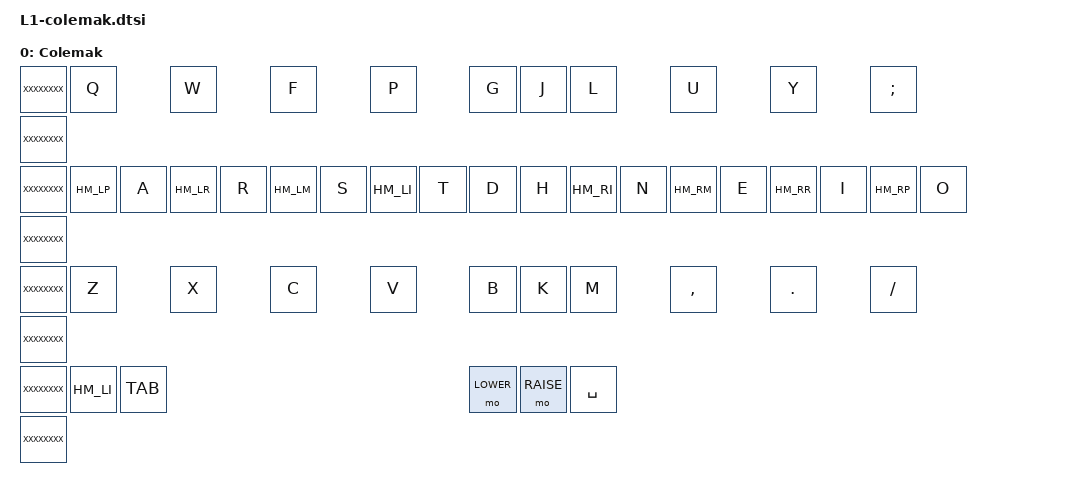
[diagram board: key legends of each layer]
/**
 *
 */

/ {
  keymap {
    compatible = "zmk,keymap";

    colemak_layer {
        label = "Colemak";
        bindings = <
//					  ╭───────────────┬───────────────┬───────────────┬───────────────┬───────────────╮   ╭───────────────┬───────────────┬───────────────┬───────────────┬───────────────╮
	XXXXXXXX			&kp Q           &kp W           &kp F           &kp P           &kp G               &kp J           &kp L           &kp U           &kp Y           &kp SEMI
	XXXXXXXX	//	├───────────────┼───────────────┼───────────────┼───────────────┼───────────────┤   ├───────────────├───────────────┼───────────────┼───────────────┼───────────────┤
	XXXXXXXX			HM_LP A      	HM_LR R      	HM_LM S      	HM_LI T      	&kp D               &kp H           HM_RI N     	HM_RM E   		HM_RR I      	HM_RP O
	XXXXXXXX	//	├───────────────┼───────────────┼───────────────┼───────────────┼───────────────┤   ├───────────────├───────────────┼───────────────┼───────────────┼───────────────┤
	XXXXXXXX			&kp Z     		&kp X      		&kp C      		&kp V       	&kp B               &kp K           &kp M       	&kp COMMA  		&kp DOT   		&kp FSLH
	XXXXXXXX	//	╰───────────────┴───────────────┼───────────────┼───────────────┼───────────────┤   ├───────────────├───────────────┼───────────────┼───────────────┴───────────────╯
	XXXXXXXX       														HM_LI TAB		&mo LOWER		&mo RAISE		&kp SPACE
//                                                                  ╰───────────────┴───────────────╯   ╰───────────────┴───────────────╯
	XXXXXXXX
			>;
		};
    };
};
